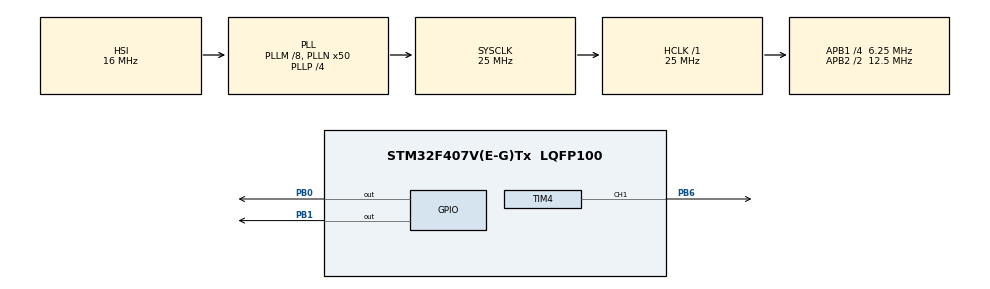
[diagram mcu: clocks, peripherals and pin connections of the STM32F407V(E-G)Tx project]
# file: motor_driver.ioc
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Mcu.Family=STM32F4
Mcu.Name=STM32F407V(E-G)Tx
Mcu.Package=LQFP100
NVIC.PriorityGroup=NVIC_PRIORITYGROUP_0
PB0.GPIO_PuPd=GPIO_NOPULL
PB0.Signal=GPIO_Output
PB1.GPIO_PuPd=GPIO_NOPULL
PB1.Signal=GPIO_Output
PB6.Signal=S_TIM4_CH1
ProjectManager.HeapSize=0x200
ProjectManager.StackSize=0x400
ProjectManager.TargetToolchain=STM32CubeIDE
RCC.48MHZClocksFreq_Value=14285714.285714285
RCC.AHBFreq_Value=25000000
RCC.APB1CLKDivider=RCC_HCLK_DIV4
RCC.APB1Freq_Value=6250000
RCC.APB1TimFreq_Value=12500000
RCC.APB2CLKDivider=RCC_HCLK_DIV2
RCC.APB2Freq_Value=12500000
RCC.APB2TimFreq_Value=25000000
RCC.CortexFreq_Value=25000000
RCC.HCLKFreq_Value=25000000
RCC.HSE_VALUE=8000000
RCC.HSI_VALUE=16000000
RCC.LSE_VALUE=32768
RCC.PLLM=8
RCC.PLLN=50
RCC.PLLP=RCC_PLLP_DIV4
RCC.PLLQ=7
RCC.SYSCLKFreq_VALUE=25000000
RCC.SYSCLKSource=RCC_SYSCLKSOURCE_PLLCLK
RCC.VCOOutputFreq_Value=100000000
SH.S_TIM4_CH1.0=TIM4_CH1,PWM Generation1 CH1
TIM4.Channel-PWM\ Generation1\ CH1=TIM_CHANNEL_1
TIM4.Period=999
TIM4.Prescaler=83
board=STM32F407G-DISC1

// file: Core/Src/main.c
/* USER CODE BEGIN Header */
/**
  ******************************************************************************
  * @file           : main.c
  * @brief          : Main program body
  ******************************************************************************
  * @attention
  *
  * Copyright (c) 2025 STMicroelectronics.
  * All rights reserved.
  *
  * This software is licensed under terms that can be found in the LICENSE file
  * in the root directory of this software component.
  * If no LICENSE file comes with this software, it is provided AS-IS.
  *
  ******************************************************************************
  */
/* USER CODE END Header */
#include "main.h"

TIM_HandleTypeDef htim4;

void SystemClock_Config(void);
static void MX_GPIO_Init(void);
static void MX_TIM4_Init(void);

int main(void)
{

  /* MCU Configuration--------------------------------------------------------*/

  /* Reset of all peripherals, Initializes the Flash interface and the Systick. */
  HAL_Init();

  /* Configure the system clock */
  SystemClock_Config();

  /* Initialize all configured peripherals */
  MX_GPIO_Init();
  MX_TIM4_Init();
  /* USER CODE BEGIN 2 */

  // Start PWM
  HAL_TIM_PWM_Start(&htim4, TIM_CHANNEL_1);

  // Set direction: Forward (PB0=HIGH, PB1=LOW)
  HAL_GPIO_WritePin(GPIOB, GPIO_PIN_0, GPIO_PIN_SET);   // IN1
  HAL_GPIO_WritePin(GPIOB, GPIO_PIN_1, GPIO_PIN_RESET); // IN2

  // Set speed to 50% duty cycle (499 out of 999)
  __HAL_TIM_SET_COMPARE(&htim4, TIM_CHANNEL_1, 499);

  /* USER CODE END 2 */

  /* Infinite loop */
  while (1)
  {
	  // Ramp speed up
	    for (uint16_t speed = 0; speed <= 999; speed += 100) {
	      __HAL_TIM_SET_COMPARE(&htim4, TIM_CHANNEL_1, speed);
	      HAL_Delay(500);
	    }

	    // Reverse direction
	    HAL_GPIO_WritePin(GPIOB, GPIO_PIN_0, GPIO_PIN_RESET); // IN1
	    HAL_GPIO_WritePin(GPIOB, GPIO_PIN_1, GPIO_PIN_SET);   // IN2
	    HAL_Delay(1000);

	    // Ramp speed down
	    for (uint16_t speed = 999; speed >= 100; speed -= 100) {
	      __HAL_TIM_SET_COMPARE(&htim4, TIM_CHANNEL_1, speed);
	      HAL_Delay(500);
	    }

	    // Forward again
	    HAL_GPIO_WritePin(GPIOB, GPIO_PIN_0, GPIO_PIN_SET);
	    HAL_GPIO_WritePin(GPIOB, GPIO_PIN_1, GPIO_PIN_RESET);
	    HAL_Delay(1000);
  }
}

void SystemClock_Config(void)
{
  RCC_OscInitTypeDef RCC_OscInitStruct = {0};
  RCC_ClkInitTypeDef RCC_ClkInitStruct = {0};

  /** Configure the main internal regulator output voltage
  */
  __HAL_RCC_PWR_CLK_ENABLE();
  __HAL_PWR_VOLTAGESCALING_CONFIG(PWR_REGULATOR_VOLTAGE_SCALE1);

  /** Initializes the RCC Oscillators according to the specified parameters
  * in the RCC_OscInitTypeDef structure.
  */
  RCC_OscInitStruct.OscillatorType = RCC_OSCILLATORTYPE_HSI;
  RCC_OscInitStruct.HSIState = RCC_HSI_ON;
  RCC_OscInitStruct.HSICalibrationValue = RCC_HSICALIBRATION_DEFAULT;
  RCC_OscInitStruct.PLL.PLLState = RCC_PLL_ON;
  RCC_OscInitStruct.PLL.PLLSource = RCC_PLLSOURCE_HSI;
  RCC_OscInitStruct.PLL.PLLM = 8;
  RCC_OscInitStruct.PLL.PLLN = 50;
  RCC_OscInitStruct.PLL.PLLP = RCC_PLLP_DIV4;
  RCC_OscInitStruct.PLL.PLLQ = 7;
  if (HAL_RCC_OscConfig(&RCC_OscInitStruct) != HAL_OK)
  {
    Error_Handler();
  }

  /** Initializes the CPU, AHB and APB buses clocks
  */
  RCC_ClkInitStruct.ClockType = RCC_CLOCKTYPE_HCLK|RCC_CLOCKTYPE_SYSCLK
                              |RCC_CLOCKTYPE_PCLK1|RCC_CLOCKTYPE_PCLK2;
  RCC_ClkInitStruct.SYSCLKSource = RCC_SYSCLKSOURCE_PLLCLK;
  RCC_ClkInitStruct.AHBCLKDivider = RCC_SYSCLK_DIV1;
  RCC_ClkInitStruct.APB1CLKDivider = RCC_HCLK_DIV4;
  RCC_ClkInitStruct.APB2CLKDivider = RCC_HCLK_DIV2;

  if (HAL_RCC_ClockConfig(&RCC_ClkInitStruct, FLASH_LATENCY_0) != HAL_OK)
  {
    Error_Handler();
  }
}

static void MX_TIM4_Init(void)
{

  TIM_MasterConfigTypeDef sMasterConfig = {0};
  TIM_OC_InitTypeDef sConfigOC = {0};

  htim4.Instance = TIM4;
  htim4.Init.Prescaler = 83;
  htim4.Init.CounterMode = TIM_COUNTERMODE_UP;
  htim4.Init.Period = 999;
  htim4.Init.ClockDivision = TIM_CLOCKDIVISION_DIV1;
  htim4.Init.AutoReloadPreload = TIM_AUTORELOAD_PRELOAD_DISABLE;
  if (HAL_TIM_PWM_Init(&htim4) != HAL_OK)
  {
    Error_Handler();
  }
  sMasterConfig.MasterOutputTrigger = TIM_TRGO_RESET;
  sMasterConfig.MasterSlaveMode = TIM_MASTERSLAVEMODE_DISABLE;
  if (HAL_TIMEx_MasterConfigSynchronization(&htim4, &sMasterConfig) != HAL_OK)
  {
    Error_Handler();
  }
  sConfigOC.OCMode = TIM_OCMODE_PWM1;
  sConfigOC.Pulse = 0;
  sConfigOC.OCPolarity = TIM_OCPOLARITY_HIGH;
  sConfigOC.OCFastMode = TIM_OCFAST_DISABLE;
  if (HAL_TIM_PWM_ConfigChannel(&htim4, &sConfigOC, TIM_CHANNEL_1) != HAL_OK)
  {
    Error_Handler();
  }
  HAL_TIM_MspPostInit(&htim4);

}

static void MX_GPIO_Init(void)
{
  GPIO_InitTypeDef GPIO_InitStruct = {0};

  /* GPIO Ports Clock Enable */
  __HAL_RCC_GPIOB_CLK_ENABLE();

  /*Configure GPIO pin Output Level */
  HAL_GPIO_WritePin(GPIOB, GPIO_PIN_0|GPIO_PIN_1, GPIO_PIN_RESET);

  /*Configure GPIO pins : PB0 PB1 */
  GPIO_InitStruct.Pin = GPIO_PIN_0|GPIO_PIN_1;
  GPIO_InitStruct.Mode = GPIO_MODE_OUTPUT_PP;
  GPIO_InitStruct.Pull = GPIO_NOPULL;
  GPIO_InitStruct.Speed = GPIO_SPEED_FREQ_LOW;
  HAL_GPIO_Init(GPIOB, &GPIO_InitStruct);

}

void Error_Handler(void)
{
  __disable_irq();
  while (1)
  {
  }
}
